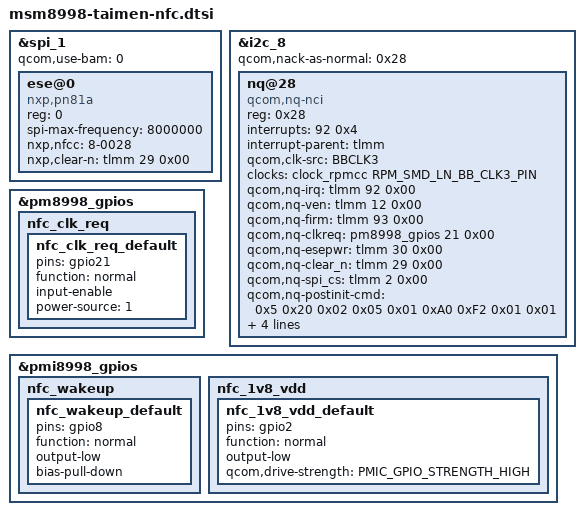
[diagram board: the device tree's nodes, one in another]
/* Copyright (c) 2017, The Linux Foundation. All rights reserved.
 *
 * This program is free software; you can redistribute it and/or modify
 * it under the terms of the GNU General Public License version 2 and
 * only version 2 as published by the Free Software Foundation.
 *
 * This program is distributed in the hope that it will be useful,
 * but WITHOUT ANY WARRANTY; without even the implied warranty of
 * MERCHANTABILITY or FITNESS FOR A PARTICULAR PURPOSE.  See the
 * GNU General Public License for more details.
 */

/* NFC SPI (eSE) */
&spi_1 {
	status = "ok";
	/* DMA is only working intermittently - disable. */
	qcom,use-bam = <0>;

	ese@0 {
		compatible = "nxp,pn81a";
		reg = <0>;
		spi-max-frequency = <8000000>;
		/* i2c NFC device handles eSE power:
		 * i2c_8, reg 0x28
		 */
		nxp,nfcc = "8-0028";
		nxp,clear-n = <&tlmm 29 0x00>;
	};
};

&i2c_8 { /* BLSP1 QUP8 (NFC) */
	status = "okay";
	qcom,nack-as-normal = <0x28>;
	nq@28 {
	compatible = "qcom,nq-nci";
	reg = <0x28>;
	interrupts = <92 0x4>;
	interrupt-parent = <&tlmm>;
	interrupt-names = "nfc_irq";
	clock-names = "ref_clk";
	qcom,clk-src = "BBCLK3";
	clocks = <&clock_rpmcc RPM_SMD_LN_BB_CLK3_PIN>;
	qcom,nq-irq = <&tlmm 92 0x00>;
	qcom,nq-ven = <&tlmm 12 0x00>;
	qcom,nq-firm = <&tlmm 93 0x00>;
	qcom,nq-clkreq = <&pm8998_gpios 21 0x00>;
	qcom,nq-esepwr = <&tlmm 30 0x00>;
	qcom,nq-clear_n = <&tlmm 29 0x00>;
	qcom,nq-spi_cs = <&tlmm 2 0x00>;
	qcom,nq-postinit-cmd = /bits/ 8
		<0x5 0x20 0x02 0x05 0x01 0xA0 0xF2 0x01 0x01>;
	pinctrl-names = "nfc_active", "nfc_suspend";
	pinctrl-0 = <&nfc_int_active &nfc_enable_active &nfc_clk_req_default>;
	pinctrl-1 = <&nfc_int_suspend &nfc_enable_suspend &nfc_clk_req_default>;
	};
};

&pm8998_gpios {
	/* GPIO 21 (NFC_CLK_REQ) */
	nfc_clk_req {
		nfc_clk_req_default: nfc_clk_req_default {
			pins = "gpio21";
			function = "normal";
			input-enable; /* Input */
			power-source = <1>;
		};
	};
};


&pmi8998_gpios {
	nfc_wakeup {  /*GPIO_8 NFC_WAKEUP Not configured in driver yet nq-nci.c*/
		nfc_wakeup_default: nfc_wakeup_default {
			pins = "gpio8";
			function = "normal";             /* GPIO */
			output-low;                /* Output */
			bias-pull-down;                /* Pulldown 10uA */
		};
	};
};


&pmi8998_gpios {
	/* nfc_1v8_vdd */
	nfc_1v8_vdd {
		nfc_1v8_vdd_default: nfc_1v8_vdd_default {
			pins = "gpio2";
			function = "normal";
			output-low;
			qcom,drive-strength = <PMIC_GPIO_STRENGTH_HIGH>;        /* High */
		};
	};
};
